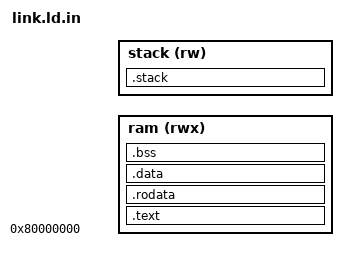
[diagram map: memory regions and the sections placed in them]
OUTPUT_ARCH(riscv)

/* Generated from link.ld.in by CMake (configure_file). The RAM size is
   board-driven via COREJACK_RAM_BYTES (default 1 MiB); see
   cfg/boards/<board>.yaml: memory.ram_bytes. The stack occupies the top
   COREJACK_STACK_BYTES of RAM, so the usable code/data region is the
   remainder below it. */

MEMORY
{
  ram   (rwx) : ORIGIN = 0x80000000, LENGTH = @COREJACK_RAM_REGION_BYTES@
  stack (rw)  : ORIGIN = @COREJACK_STACK_ORIGIN@, LENGTH = @COREJACK_STACK_BYTES@
}

_min_stack   = 0x1000;
_stack_len   = LENGTH(stack);
_stack_start = ORIGIN(stack) + LENGTH(stack);
_stack_end   = ORIGIN(stack);

_ram_start = ORIGIN(ram);
_ram_end   = ORIGIN(ram) + LENGTH(ram);
_ram_size  = LENGTH(ram);

_entry_point = _vectors_start + 0x80;
ENTRY(_entry_point)

SECTIONS
{
  .text : {
    . = ALIGN(4);
    _vectors_start = .;
    KEEP(*(.vectors))
    _vectors_end = .;
    KEEP(*(.init))
    *(.text)
    *(.text.*)
    . = ALIGN(4);
  } > ram

  .rodata : {
    . = ALIGN(4);
    *(.srodata)
    *(.srodata.*)
    *(.rodata)
    *(.rodata.*)
    . = ALIGN(4);
  } > ram

  .data : {
    . = ALIGN(4);
    _sdata = .;
    *(.sdata)
    *(.sdata.*)
    *(.data)
    *(.data.*)
    . = ALIGN(4);
    _edata = .;
  } > ram

  .bss (NOLOAD) : {
    . = ALIGN(4);
    _bss_start = .;
    *(.sbss)
    *(.sbss.*)
    *(.bss)
    *(.bss.*)
    *(COMMON)
    _bss_end = .;
    . = ALIGN(4);
  } > ram

  .stack (NOLOAD) : {
    . = ALIGN(4);
    . = . + _min_stack;
    . = ALIGN(4);
    _stack = .;
  } > stack
}

uart0_base = 0x10000000;
sim_ctrl   = 0x10002000;
